# RZT2H register map
Vendor: Renesas Electronics Corporation; Series: RZT; File version: 1.00.00
CPU: other r0p0, little endian, MPU, no FPU, VTOR, 4 interrupt priority bits, 624 interrupts
Registers are 32-bit, read-write, reset 0x0 unless marked. A register's access mark holds for its fields unless they carry their own. Offsets are from the block's base; [hi:lo] are bit positions; {n}, {i} and the like mark numbered series; 'fields as' and 'values as' point back to an identical list; <NAME> marks a mode.

## LCDC — LCD Controller
Base 0x920C0000
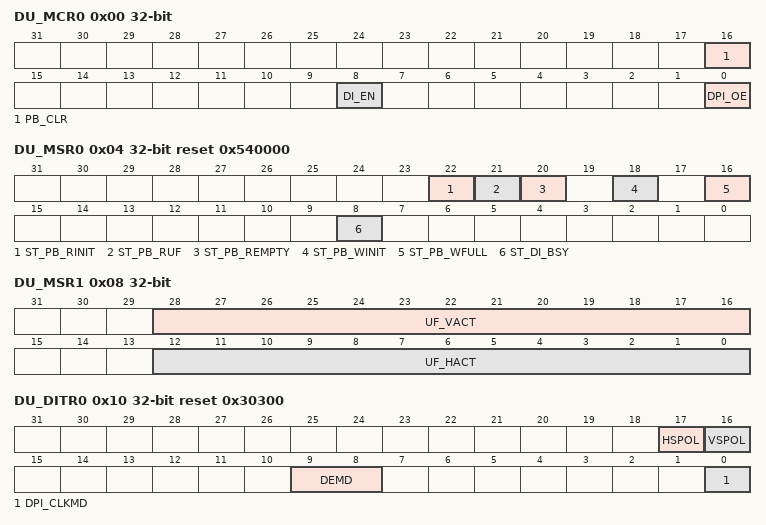
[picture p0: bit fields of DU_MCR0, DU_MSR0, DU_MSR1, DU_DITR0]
0x00 DU_MCR0 — DU Module Control Register 0
  [16] PB_CLR — Clear PBUF pointers
  [8] DI_EN
    0=Disable; 1=Enable
  [0] DPI_OE — Display parallel interface output enable
    0=Disable; 1=Enable
0x04 DU_MSR0 ro reset 0x540000 — DU Module Status Register 0
  [22] ST_PB_RINIT
    0=Not cleared; 1=Cleared (initial value)
  [21] ST_PB_RUF
    0=Not occur PBUF underflow; 1=Occur PBUF underflow
  [20] ST_PB_REMPTY
    0=Not empty; 1=Empty
  [18] ST_PB_WINIT
    0=Not cleared; 1=Cleared (initial value)
  [16] ST_PB_WFULL
    0=Not full; 1=Full
  [8] ST_DI_BSY
    0=Idle; 1=Busy
0x08 DU_MSR1 ro — DU Module Status Register 1
  [28:16] UF_VACT — Vactive counter when the PBUF underflow occurs
  [12:0] UF_HACT — Hactive counter when the PBUF underflow occurs
0x0C DU_IMR0 — DU Interrupt Mask Register 0
  [0] IM_PB_RUF
    0=Not mask interrupt; 1=Mask interrupt
0x10 DU_DITR0 reset 0x30300 — DU Display I/F Timing Register 0
  [17] HSPOL — hsync polarity
    0=Low active; 1=High active
  [16] VSPOL — vsync polarity
    0=Low active; 1=High active
  [9:8] DEMD
    0=Fixed to Low; 3=Data enable (High active)
  [0] DPI_CLKMD
    0=Through output; 1=Inversion output
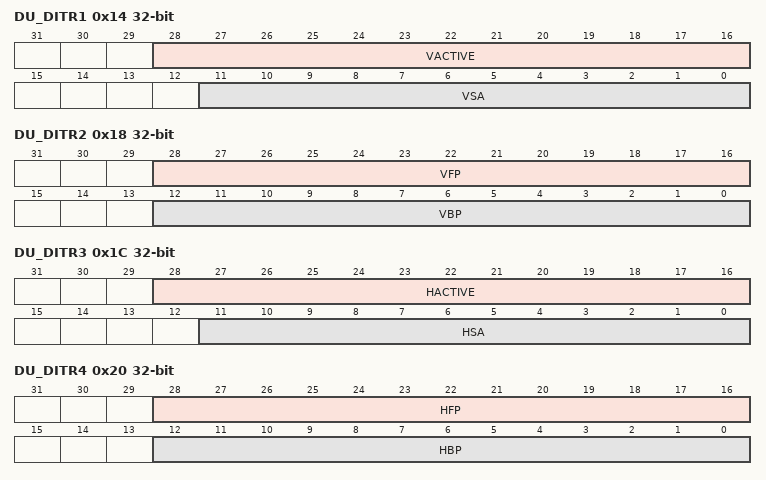
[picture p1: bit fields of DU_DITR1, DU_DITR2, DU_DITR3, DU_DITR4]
0x14 DU_DITR1 — DU Display I/F Timing Register 1
  [28:16] VACTIVE — The number of lines in the Vactive period
  [11:0] VSA — The number of lines in the Vsync period
0x18 DU_DITR2 — DU Display I/F Timing Register 2
  [28:16] VFP — The number of lines in the Vfront period
  [12:0] VBP — The number of lines in the Vback period
0x1C DU_DITR3 — DU Display I/F Timing Register 3
  [28:16] HACTIVE — The number of cycles (pixels) in the Hactive period
  [11:0] HSA — The number of cycles in the Hsync period
0x20 DU_DITR4 — DU Display I/F Timing Register 4
  [28:16] HFP — The number of cycles in the Hfront period
  [12:0] HBP — The number of cycles in the Hback period
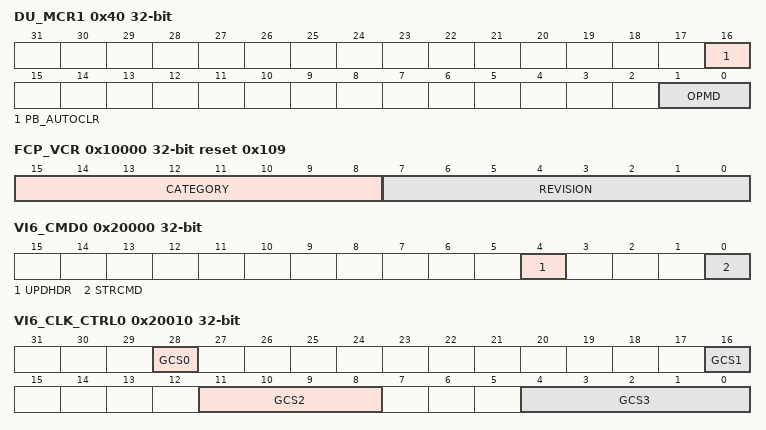
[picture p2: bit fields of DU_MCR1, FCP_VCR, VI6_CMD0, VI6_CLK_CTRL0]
0x40 DU_MCR1 — DU Module Control Register 1
  [16] PB_AUTOCLR — PBUF pointers auto clear enable
    0=Not clear until DU_MCR0.PB_CLR is asserted; 1=Clear during blanking. (according to DU_MCR1.OPMD)
  [1:0] OPMD — Operation mode
    0=After frame end, LIFC wait, and PBUF pointers are cleared if DU_MCR1.PB_AUTOCLR is set to 1; 1=After line end, LIFC wait, and PBUF pointers are cleared if DU_MCR1.PB_AUTOCLR is set to 1; 3=LIFC always request to VSPD. PBUF pointers are not cleared until DU_MCR0.PB_CLR is set to 1.
0x4C DU_PBCR0 reset 0x1F — DU PBUF Control Register 0
  [4:0] PB_DEP — Valid PBUF depth
0x50 DU_PBCR1 — DU PBUF Control Register 1
  [0] PB_RUFOP
    0=Continue outputting invalid data; 1=Output DU_PBCR2.PB_RUFDAT
0x54 DU_PBCR2 — DU PBUF Control Register 2
  [23:0] PB_RUFDAT
0x10000 FCP_VCR ro reset 0x109 — FCPVD Version Control Register
  [15:8] CATEGORY
  [7:0] REVISION
    9=FCP revision is the Simple LCDC
0x20000 VI6_CMD0 — VSPD Start Register 0
  [4] UPDHDR — Reserved state of updating Display List Header (DLH) address
    0=NOP [Write] Not reserved to update DLH address [Read]; 1=Do not set this bit to 1 [Write] Reserved to update DLH address [Read]
  [0] STRCMD — Start reservation of WPF
    0=Start reservation of WPF0 is canceled. [Write] Starting VSPD is not reserved. [Read]; 1=Start reservation of WPF0 is set. [Write] Starting VSPD is reserved. [Read]
0x20010 VI6_CLK_CTRL0 — Clock Control Register 0
  [28] GCS0, [16] GCS1, [11:8] GCS2, [4:0] GCS3
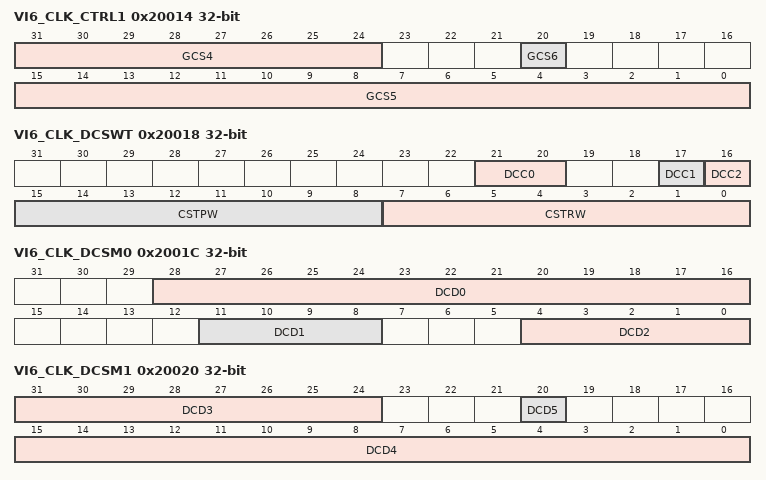
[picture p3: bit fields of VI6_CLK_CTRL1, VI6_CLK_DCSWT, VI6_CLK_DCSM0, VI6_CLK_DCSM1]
0x20014 VI6_CLK_CTRL1 — Clock Control Register 1
  [31:24] GCS4, [20] GCS6, [15:0] GCS5
0x20018 VI6_CLK_DCSWT — Dynamic Clock Stop Control Register
  [21:20] DCC0
  [17] DCC1
  [16] DCC2
  [15:8] CSTPW — Dynamic Clock Stop Control 1
  [7:0] CSTRW — Dynamic Clock Stop Control 2
0x2001C VI6_CLK_DCSM0 — Dynamic Clock Stop Disable Register 0
  [28:16] DCD0, [11:8] DCD1, [4:0] DCD2
0x20020 VI6_CLK_DCSM1 — Dynamic Clock Stop Disable Register 1
  [31:24] DCD3, [20] DCD5, [15:0] DCD4
0x20028 VI6_SRESET — Software Reset Register
  [0] SRST0 — WPF0 Software Reset
    0=NOP; 1=WPF0 software reset
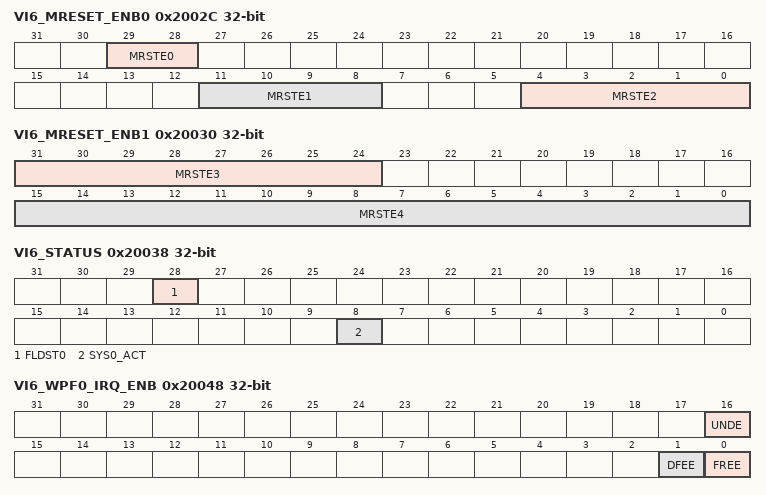
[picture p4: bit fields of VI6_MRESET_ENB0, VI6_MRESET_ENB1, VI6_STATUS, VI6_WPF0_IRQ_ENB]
0x2002C VI6_MRESET_ENB0 — Module Reset Enable Register 0
  [29:28] MRSTE0, [11:8] MRSTE1, [4:0] MRSTE2
0x20030 VI6_MRESET_ENB1 — Module Reset Enable Register 1
  [31:24] MRSTE3, [15:0] MRSTE4
0x20034 VI6_MRESET — Module Reset Issuing Register
  [0] MRST
0x20038 VI6_STATUS ro — Operating Status Register
  [28] FLDST0 — Field status of previous frame of WPF0
    0=Previous finished frame is TOP field; 1=Previous finished frame is BOT field
  [8] SYS0_ACT — WPF0 Operating Status
    0=WPF0 is stopped; 1=WPF0 is operating
0x20048 VI6_WPF0_IRQ_ENB — WPF0 Interrupt Enable Register
  [all] fields
    0=Interrupt disabled; 1=Interrupt enabled
  [16] UNDE
  [1] DFEE
  [0] FREE
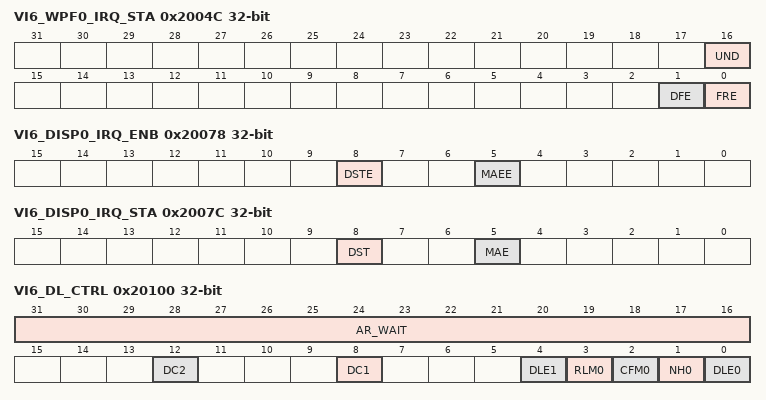
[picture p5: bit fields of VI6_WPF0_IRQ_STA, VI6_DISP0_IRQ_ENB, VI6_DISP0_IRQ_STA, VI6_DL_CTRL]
0x2004C VI6_WPF0_IRQ_STA — WPF0 Interrupt Status Register
  [all] fields
    0=No interrupt. [Read] The interrupt status is cleared to 0. [Write]; 1=Interrupt activated. [Read] Hold the interrupt status value. [Write]
  [16] UND — Interrupt Status and Clear for WPF0 Underrun in case of DU connection
  [1] DFE — Interrupt Status and Clear for WPF0 Display List Frame End
  [0] FRE — Interrupt Status and Clear for WPF0 Frame End
0x20078 VI6_DISP0_IRQ_ENB — Display-0 Interrupt Enable Register
  [8] DSTE
    0=Interrupt disabled; 1=Interrupt enabled
  [5] MAEE
    0=Interrupt disabled; 1=Interrupt enabled
0x2007C VI6_DISP0_IRQ_STA — Display-0 Interrupt Status Register
  [8] DST — Interrupt Status and Clear for Display Start
    values as the fields of VI6_WPF0_IRQ_STA
  [5] MAE — Interrupt Status and Clear for Display Read Data End
    values as the fields of VI6_WPF0_IRQ_STA
0x20100 VI6_DL_CTRL — Display List Control Register
  [31:16] AR_WAIT — Display List Control Setting
  [12] DC2
  [8] DC1
  [4] DLE1 — This bit does not affect anything VSPD. (NOP)
  [3] RLM0 — Loading two plane Registers Mode for WPF0
    0=Reserved status (VI6_CMD0.UPDHDR) is accepted by next_frame_auto_start. Two plane registers are also downloaded by next_frame_auto_start.; 1=Reserved status (VI6_CMD0.UPDHDR) is not accepted by next_frame_auto_start. pNext_header in previous frame's DLH is used for loading Display List. Two plane registers are not downloaded by next_frame_auto_start either.
  [2] CFM0 — Continuous Frame Mode for Header-less Display List for WPF0
    0=Stopped at the end of every frame; 1=The next frame is automatically started
  [1] NH0 — Header-less Display List Mode
    0=Use Display List Header (Normal DL Mode); 1=Do not use Display List Header (Header-less Mode)
  [0] DLE0 — Display List Enable/Disable for WPF0
    0=The display list function is disabled; 1=The display list function is enabled
0x20104 VI6_DL_HDR_ADDR0 — Display List-0 Header Address Register
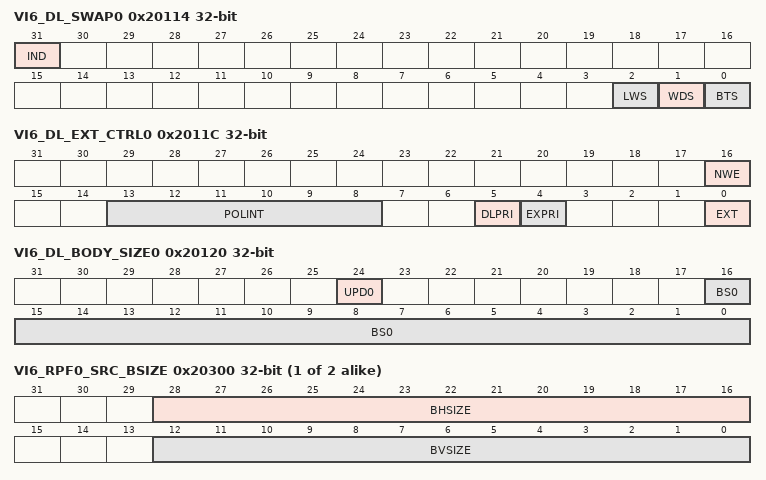
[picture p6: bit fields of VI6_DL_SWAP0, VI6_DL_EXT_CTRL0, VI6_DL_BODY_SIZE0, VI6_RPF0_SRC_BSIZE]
0x20114 VI6_DL_SWAP0 — Display List-0 Data Swapping Register
  [31] IND — Enabling independent swap setting per WPF
    0=Display list swap for WPF1 is specified by LWS, WDS, and BTS in VI6_DL_SWAP0; 1=Display list swap for WPF1 is specified by LWS, WDS, and BTS in VI6_DL_SWAP1
  [2] LWS — Display List Data Swapping in long word Units
    0=Data swapping in long word (32-bit) units is disabled; 1=Data swapping in long word (32-bit) units is enabled
  [1] WDS — Display List Data Swapping in Word Units
    0=Data swapping in word (16-bit) units is disabled; 1=Data swapping in word (16-bit) units is enabled
  [0] BTS — Display List Data Swapping in Byte Units
    0=Data swapping in byte (8-bit) units is disabled; 1=Data swapping in byte (8-bit) units is enabled
0x2011C VI6_DL_EXT_CTRL0 — Extended Display List-0 Control Register
  [16] NWE — No Wait for Polling
  [13:8] POLINT — Extended Display List Command Control
  [5] DLPRI — Display List Control 0
  [4] EXPRI — Display List Control 1
  [0] EXT — Extended Display List for WPF0
    0=No extended display lists are used; 1=Extended display lists are used
0x20120 VI6_DL_BODY_SIZE0 — Display List Body Size Register 0
  [24] UPD0 — Update Flag
    0=Updating display list for the next frame is not reserved; 1=Updating display list for the next frame is reserved
  [16:0] BS0 — Header-less Display List Body Size (WPF0)
0x20130 VI6_DL_HDR_REF_ADDR0 ro — Display List-0 Header Reference Address Register
{0x20300+0x100*i} VI6_RPF{i}_SRC_BSIZE (i=0..1) — RPFn Basic Read Size Register
  [28:16] BHSIZE — Horizontal Size of RPF Basic Read Area
  [12:0] BVSIZE — Vertical Size of RPF Basic Read Area
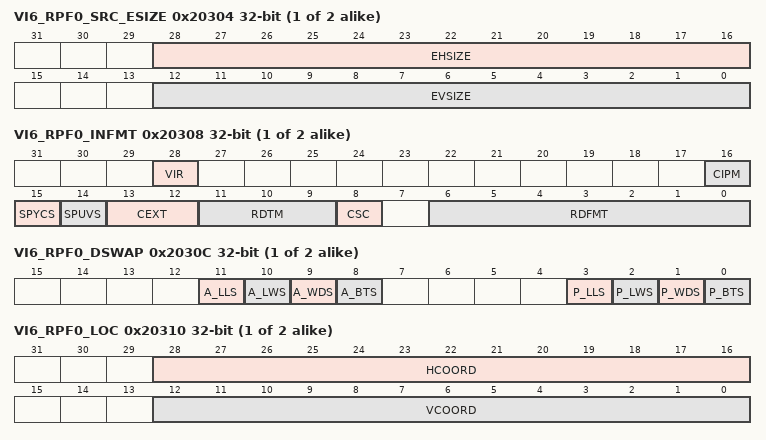
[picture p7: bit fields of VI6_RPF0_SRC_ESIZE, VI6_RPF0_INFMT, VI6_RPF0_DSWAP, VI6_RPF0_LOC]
{0x20304+0x100*i} VI6_RPF{i}_SRC_ESIZE (i=0..1) — RPFn Extended Read Size Register
  [28:16] EHSIZE — RPF Extended Horizontal Read Size
  [12:0] EVSIZE — RPF Extended Vertical Read Size
{0x20308+0x100*i} VI6_RPF{i}_INFMT (i=0..1) — RPFn Input Format Register
  [28] VIR — Virtual Input Enable
    0=RPF0 uses general input; 1=RPF0 uses virtual input
  [16] CIPM — Horizontal Chrominance Interpolation Method Setting
    0=The nearest-neighbor method is used for horizontal chrominance interpolation; 1=The bilinear method is used for horizontal chrominance interpolation
  [15] SPYCS — RPF Input Mode Setting 1
  [14] SPUVS — RPF Input Mode Setting 2
  [13:12] CEXT — Lower-Bit Color Data Extension Method Setting
    0=Lower-order bits of color data are extended with 0; 1=Upper-order bits of color data are copied to the lower-order bits; 2=Lower-order bits of color data are extended with 0. The maximum value is limited to 0xFF.; 3=Setting prohibited
  [11:9] RDTM — CSC Conversion Expression Setting
    0=BT.601 YCbCr [16,235/240] <-> RGB [0,255]; 1=BT.601 YCbCr [0,255] <-> RGB [0,255]; 2=BT.709 YCbCr [16,235/240] <-> RGB [0,255]; 3=BT.709 YCbCr [16,235/240] <-> RGB [16,235]; other=Others (Setting prohibited.)
  [8] CSC — Color Space Conversion Enable
    0=Color space conversion is disabled; 1=Color space conversion is enabled
  [6:0] RDFMT — RPF Input Image Format Setting
{0x2030C+0x100*i} VI6_RPF{i}_DSWAP (i=0..1) — RPFn Data Swapping Register
  [11] A_LLS — alpha Plane Data Swapping in LONG LWORD Units
    0=Data swapping in LONG LWORD (64-bit) units is disabled; 1=Data swapping in LONG LWORD (64-bit) units is enabled
  [10] A_LWS — alpha Plane Data Swapping in long word Units
    values as VI6_DL_SWAP0.LWS
  [9] A_WDS — alpha Plane Data Swapping in Word Units
    0=Data swapping in Word (16-bit) units is disabled; 1=Data swapping in Word (16-bit) units is enabled
  [8] A_BTS — alpha Plane Data Swapping in Byte Units
    0=Data swapping in Byte (8-bit) units is disabled; 1=Data swapping in Byte (8-bit) units is enabled
  [3] P_LLS — Picture Plane Data Swapping in LONG LWORD Units
    values as A_LLS
  [2] P_LWS — Picture Plane Data Swapping in long word Units
    values as VI6_DL_SWAP0.LWS
  [1] P_WDS — Picture Plane Data Swapping in Word Units
    values as A_WDS
  [0] P_BTS — Picture Plane Data Swapping in Byte Units
    values as A_BTS
{0x20310+0x100*i} VI6_RPF{i}_LOC (i=0..1) — RPFn Display Location Register
  [28:16] HCOORD — Horizontal Coordinate of Sublayer Display Location on Master Layer
  [12:0] VCOORD — Vertical Coordinate of Sublayer Display Location on Master Layer
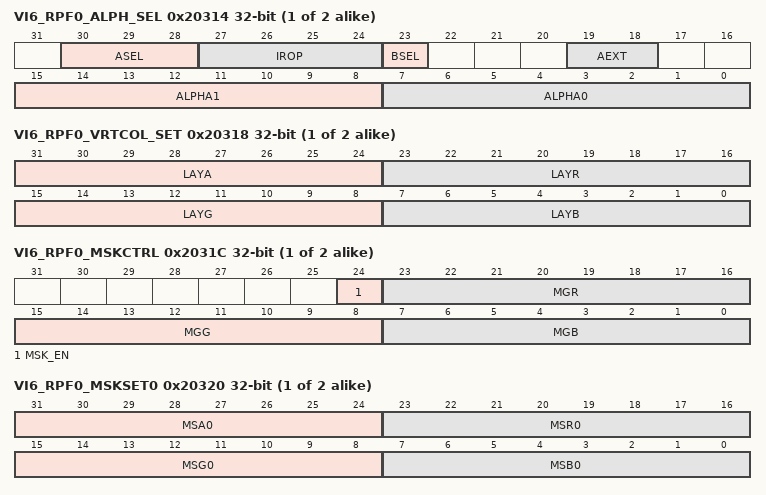
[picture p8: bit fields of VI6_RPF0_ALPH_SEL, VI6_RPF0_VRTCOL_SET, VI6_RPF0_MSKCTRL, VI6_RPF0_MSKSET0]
{0x20314+0x100*i} VI6_RPF{i}_ALPH_SEL (i=0..1) — RPFn alpha Plane Selection Control Register
  [30:28] ASEL — alpha Format and Processing Method Select
    0=1, 4, or 8-bit packed alpha + plane alpha (IROP != 0, 5, 10, 15) The alpha bit field in 1, 4, or 8-bit packed alpha is handled as transparency information. Be sure to specify the packed format that includes alpha through VI6_RPFn_INFMT.RDFMT. When VI6_RPFn_MSKCTRL.MSK_EN is 0 and the IROP bit value is not 0, 5, 10, or 15, the alpha plane should be read as mask information. Specify the number of alpha data bits (BSEL) stored in the alpha plane and the alpha plane read start address (VI6_RPFn_SRCM_ADDR_AI). When the IROP bits are set to 0, 5, 10, or 15, the alpha plane is not read.; 1=8-bit plane alpha The 8-bit alpha plane is read from external RAM as transparency information. When the packed RGB format has a bit field for alpha, the information in the alpha bit field is discarded. The alpha plane read start address (VI6_RPFn_SRCM_ADDR_AI) should be specified. The alpha value goes through the 8-bit transparent alpha generator shown in without change. When VI6_RPFn_MSKCTRL.MSK_EN is 0, IROP operation cannot be executed; set the IROP bits to 0 in this case. When VI6_RPFn_MSKCTRL.MSK_EN is 1. IROP operation can be executed.; 2=1-bit packed alpha + plane alpha (IROP != 0, 5, 10, 15) The 1-bit packed alpha input is converted by the 8-bit transparent alpha generator shown in according to the ALPHA0/1 setting into the 8-bit alpha value as transparency information. Select the packed input format that includes a 1-bit alpha field. When VI6_RPFn_MSKCTRL.MSK_EN is 0 and the IROP value is not 0, 5, 10, or 15, the alpha plane should be read as mask information. Specify the number of alpha data bits (BSEL) stored in the alpha plane and the alpha plane read start address (VI6_RPFn_SRCM_ADDR_AI). When the IROP bits are set to 0, 5, 10, or 15, the alpha plane is not read.; 3=1-bit plane alpha The 1-bit alpha plane is read from external RAM and converted by the 8-bit transparent alpha generator shown in according to the ALPHA0/1 setting into the 8-bit alpha value as transparency information. When the packed RGB format has a bit field for alpha, the information in the alpha bit field is discarded. The alpha plane read start address (VI6_RPFn_SRCM_ADDR_AI) should be specified. When VI6_RPFn_MSKCTRL.MSK_EN is 0, IROP operation cannot be executed; set the IROP bits to 0 in this case. When VI6_RPFn_MSKCTRL.MSK_EN is 1. IROP operation can be executed.; 4=Fixed alpha The fixed alpha value (VI6_RPFn_VRTCOL_SET.LAY A value) is output from the RPF. IROP operation cannot be executed; set the IROP bits to 0 in this case.; other=Others (Setting prohibited.)
  [27:24] IROP — IROP Operation Setting
    0=NOP(D); 1=AND(S & D); 2=AND_REVERSE(S & ~D); 3=COPY(S); 4=AND_INVERTED(~S & D); 5=CLEAR(0); 6=XOR(S ^ D); 7=OR(S | D); 8=NOR(~(S | D)); 9=EQUIV(~(S ^ D)); 10=INVERT(~D); 11=OR_REVERSE(S | ~D); 12=COPY_INVERTED(~S); 13=OR_INVERTED(~S | D); 14=NAND(~(S & D)); 15=SET(all 1)
  [23] BSEL — alpha Bit Count Conversion Selection for 1-Bit Mask Generator
    0=8-bit alpha is converted to 1-bit alpha through the 1-bit mask generator. When the 8-bit alpha value input to the RPF is not 0, it is converted to 1b; when the value is 0, it is converted to 0b.; 1=alpha value goes through the 1-bit mask generator. The 1-bit alpha value input to the RPF is output through the 1-bit mask generator without change.
  [19:18] AEXT — Lower-Bit alpha Value Extension Method Set
    0=The lower-order bits of alpha value are extended with 0; 1=The upper-order bits of alpha value are copied to the lower-order bits; 2=The lower-order bits of alpha value are extended with 0. The maximum value is limited to 0xFF.; 3=Setting prohibited
  [15:8] ALPHA1 — 8-Bit alpha Value Output when 1-Bit alpha Value is 1
  [7:0] ALPHA0 — 8-Bit alpha Value Output when 1-Bit alpha Value is 0
{0x20318+0x100*i} VI6_RPF{i}_VRTCOL_SET (i=0..1) — RPFn Virtual Plane Color Information Register
  [31:24] LAYA — Virtual-Input Fixed alpha Value
  [23:16] LAYR — Virtual-Input Fixed R/Cr Component Value
  [15:8] LAYG — Virtual-Input Fixed G/Y Component Value
  [7:0] LAYB — Virtual-Input Fixed B/Cb Component Value
{0x2031C+0x100*i} VI6_RPF{i}_MSKCTRL (i=0..1) — RPFn Mask Control Register
  [24] MSK_EN — Mask Generation Specification
    0=A 1-bit mask value is generated according to the input alpha plane value. When the input alpha is in the 1-bit format (VI6_RPFn_ALPH_SEL.BSEL = 1), the 1-bit mask value is output without change. When the input alpha is in the 8-bit format (VI6_RPFn_ALPH_SEL.BSEL = 0), the 1-bit mask value is 0 if the alpha value is 0x00; otherwise, the 1-bit mask value is 1.; 1=The R/Cr, G/Y, and B/Cb components of the image input to the destination side of the IROP operation unit are compared with the values specified in the MGR, MGG, and MGB bits, respectively. When all values match, 1 is output as the 1-bit mask value, and in other cases, 0 is output. When the generated 1-bit mask data is not used, set VI6_RPFn_ALPH_SEL.IROP to 0.
  [23:16] MGR — R/Cr Comparison Value for 1-Bit alpha Generation
  [15:8] MGG — G/Y Comparison Value for 1-Bit alpha Generation
  [7:0] MGB — B/Cb Comparison Value for 1-Bit alpha Generation
{0x20320+0x100*i} VI6_RPF{i}_MSKSET0 (i=0..1) — RPFn IROP-SRC Input Value Register 0
  [31:24] MSA0 — IROP-Source Input alpha Value when 1-Bit alpha is 0
  [23:16] MSR0 — IROP-Source Input R/Cr Value when 1-Bit alpha is 0
  [15:8] MSG0 — IROP-Source Input G/Y Value when 1-Bit alpha is 0
  [7:0] MSB0 — IROP-Source Input B/Cb Value when 1-Bit alpha is 0
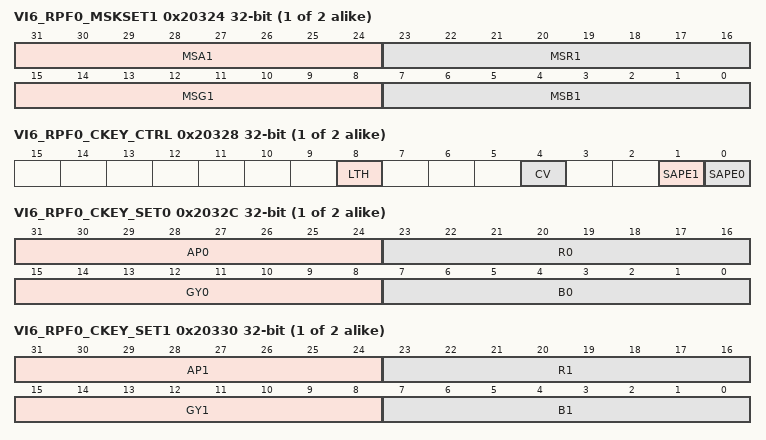
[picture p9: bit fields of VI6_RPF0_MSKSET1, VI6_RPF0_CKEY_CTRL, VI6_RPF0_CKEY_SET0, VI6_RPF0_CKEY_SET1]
{0x20324+0x100*i} VI6_RPF{i}_MSKSET1 (i=0..1) — RPFn IROP-SRC Input Value Register 1
  [31:24] MSA1 — IROP-Source Input alpha Value when 1-Bit alpha is 1
  [23:16] MSR1 — IROP-Source Input R/Cr Value when 1-Bit alpha is 1
  [15:8] MSG1 — IROP-Source Input G/Y Value when 1-Bit alpha is 1
  [7:0] MSB1 — IROP-Source Input B/Cb Value when 1-Bit alpha is 1
{0x20328+0x100*i} VI6_RPF{i}_CKEY_CTRL (i=0..1) — RPFn Color Keying Control Register
  [8] LTH — Transparent color-luma Threshold Mode Enable/Disable
    0=Luma threshold mode is disabled (Matched color mode); 1=Luma threshold mode is enabled
  [4] CV — Color Replacement Control
    0=Color replacement function is disabled (transparent color mode); 1=Color replacement function is enabled
  [1] SAPE1 — Comparison Color Data Setting 1 Enable/Disable
    0=Comparison color data setting 1 is disabled; 1=Comparison color data setting 1 is enabled
  [0] SAPE0 — Comparison Color Data Setting 0 Enable/Disable
    0=Comparison color data setting 0 is disabled; 1=Comparison color data setting 0 is enabled
{0x2032C+0x100*i} VI6_RPF{i}_CKEY_SET0 (i=0..1) — RPFn Color Keying Color Setting Register 0
  [31:24] AP0 — alpha Data in Color Keying Color Information-0
  [23:16] R0 — R/Cr Component Data in Color Keying Color Information-0
  [15:8] GY0 — G/Y Component Data in Color Keying Color Information-0
  [7:0] B0 — B/Cb Component Data in Color Keying Color Information-0
{0x20330+0x100*i} VI6_RPF{i}_CKEY_SET1 (i=0..1) — RPFn Color Keying Color Setting Register 1
  [31:24] AP1 — alpha Data in Color Keying Color Information-1
  [23:16] R1 — R/Cr Component Data in Color Keying Color Information-1
  [15:8] GY1 — G/Y Component Data in Color Keying Color Information-1
  [7:0] B1 — B/Cb Component Data in Color Keying Color Information-1
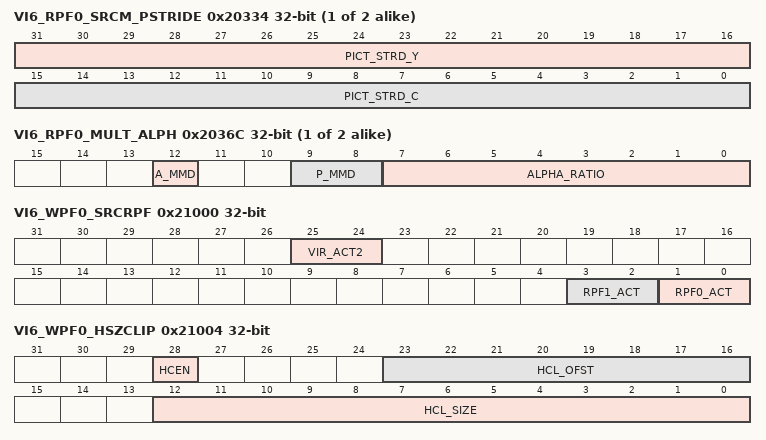
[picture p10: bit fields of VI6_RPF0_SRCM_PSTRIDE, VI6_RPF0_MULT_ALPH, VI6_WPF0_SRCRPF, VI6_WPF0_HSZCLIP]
{0x20334+0x100*i} VI6_RPF{i}_SRCM_PSTRIDE (i=0..1) — RPFn Source Picture Memory Stride Setting Register
  [31:16] PICT_STRD_Y — Memory Stride of Source Picture Y/RGB Plane
  [15:0] PICT_STRD_C — Memory Stride of Source Picture C Plane
{0x20338+0x100*i} VI6_RPF{i}_SRCM_ASTRIDE (i=0..1) — RPFn Source alpha Memory Stride Setting Register
  [15:0] ALPH_STRD — Memory Stride of Source alpha Plane
{0x2033C+0x100*i} VI6_RPF{i}_SRCM_ADDR_Y (i=0..1) — RPFn Source Y/RGB Address Register
  [31:0] SRCM_ADDR_Y — Source Image Y/RGB Plane Storing Address
{0x20340+0x100*i} VI6_RPF{i}_SRCM_ADDR_C0 (i=0..1) — RPFn Source Chroma Address Register 0
  [31:0] SRCM_ADDR_C0 — Source Image C Plane Storing Address 0
{0x20344+0x100*i} VI6_RPF{i}_SRCM_ADDR_C1 (i=0..1) — RPFn Source Chroma Address Register 1
  [31:0] SRCM_ADDR_C1 — Source Image C Plane Storing Address 1
{0x20348+0x100*i} VI6_RPF{i}_SRCM_ADDR_AI (i=0..1) — RPFn Source alpha Address Register
  [31:0] SRCM_ADDR_AI — Source Image alpha Plane Storing Address
{0x20350+0x100*i} VI6_RPF{i}_BAC (i=0..1) — RPFn Bus Access Control Register
  [16] B512 — Burst access in 512 pixels' enable
    0=Burst access in 256 pixels; 1=Burst access in 512 pixels
{0x2036C+0x100*i} VI6_RPF{i}_MULT_ALPH (i=0..1) — RPFn Multiply Alpha Control Register
  [12] A_MMD
    0=Alpha data go through multiply-alpha unit; 1=Multiply-alpha unit multiplies alpha data by specified alpha (ALPHA_RATIO[7:0])
  [9:8] P_MMD — P_MMD[1:0]
    0=Image data goes through multiply-alpha unit; 1=Multiply-alpha unit multiplies image data by specified alpha (ALPHA_RATIO[7:0]); 2=Multiply-alpha unit multiplies image data by alpha data; 3=Multiply-alpha unit multiplies image data by alpha data and specified alpha (ALPHA_RATIO[7:0])
  [7:0] ALPHA_RATIO — Multiply-alpha value
0x21000 VI6_WPF0_SRCRPF — WPF0-Source-RPF Register
  [25:24] VIR_ACT2 — Virtual RPF Start Enable in BRS
    0=The virtual RPF in the BRS is not started; 1=The virtual RPF in the BRS is started as a sublayer source RPF for the WPF0; 2=The virtual RPF in the BRS is started as the master-layer source RPF for the WPF0; 3=Setting prohibited
  [3:2] RPF1_ACT — RPF1 Start Enable
    0=RPF1 is not started; 1=RPF1 is started as a sublayer source RPF for the WPF0; 2=RPF1 is started as the master-layer source RPF for the WPF0; 3=Setting prohibited
  [1:0] RPF0_ACT — RPF0 Start Enable
    0=RPF0 is not started; 1=RPF0 is started as a sublayer source RPF for the WPF0; 2=RPF0 is started as the master-layer source RPF for the WPF0; 3=Setting prohibited
0x21004 VI6_WPF0_HSZCLIP — WPF0 Horizontal Input Size Clipping Register
  [28] HCEN — Horizontal Size Clipping Enable/Disable
    0=Horizontal size clipping is disabled; 1=Horizontal size clipping is enabled
  [23:16] HCL_OFST — Horizontal Size Clipping Offset Value Setting
  [12:0] HCL_SIZE — Horizontal Clipping Size Setting
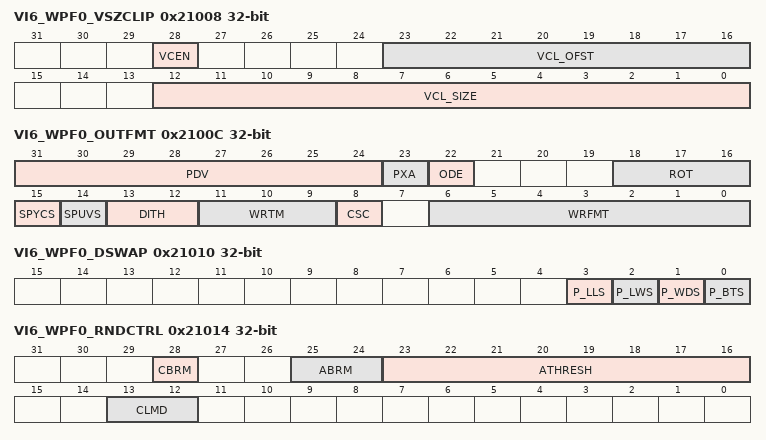
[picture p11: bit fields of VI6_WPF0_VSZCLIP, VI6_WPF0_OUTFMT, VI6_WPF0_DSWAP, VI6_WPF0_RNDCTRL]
0x21008 VI6_WPF0_VSZCLIP — WPF0 Vertical Input Size Clipping Register
  [28] VCEN — Vertical Size Clipping Enable/Disable
    0=Vertical size clipping is disabled; 1=Vertical size clipping is enabled
  [23:16] VCL_OFST — Vertical Size Clipping Offset Value Setting
  [12:0] VCL_SIZE — Vertical Clipping Size Setting
0x2100C VI6_WPF0_OUTFMT — WPF0 Output Format Register
  [31:24] PDV — PAD Value in Output Packed Data
  [23] PXA — PAD Data Select
    0=The value specified in the PDV bits is stored in the PAD shown in ; 1=The alpha value output from DPR in pixel units is stored in the PAD shown in 
  [22] ODE — Ordered Dither (mode A) Enable/Disable
    0=Ordered dither (mode A) is disabled; 1=Ordered dither (mode A) is enabled
  [18:16] ROT — Rotation Processing Select
    0=No flipping; 1=Vertical flipping
  [15] SPYCS — WPF Output Mode Setting 1
  [14] SPUVS — WPF Output Mode Setting 2
  [13:12] DITH — Ordered Dither (mode B) Enable/Disable
    0=Dithering (mode B) is disabled; 3=Dithering (mode B) is enabled; other=Others (Setting prohibited.)
  [11:9] WRTM — CSC Conversion Expression Setting
    0=BT.601 Y CbCr [16,235/240] <-> RGB [0,255]; 1=BT.601 Y CbCr [0,255] <-> RGB [0,255]; 2=BT.709 Y CbCr [16,235/240] <-> RGB [0,255]; 3=BT.709 Y CbCr [16,235/240] <-> RGB [16,235]; other=Others (Setting prohibited.)
  [8] CSC — Color Space Conversion Setting
    0=Color space is not converted; 1=Color space is converted
  [6:0] WRFMT — WPF Output Image Format Setting
0x21010 VI6_WPF0_DSWAP — WPF0 Data Swapping Register
  [3] P_LLS
    values as VI6_RPF0_DSWAP.A_LLS
  [2] P_LWS
    values as VI6_DL_SWAP0.LWS
  [1] P_WDS — WPF Output Data Swapping in Word Units
    values as VI6_DL_SWAP0.WDS
  [0] P_BTS
    values as VI6_DL_SWAP0.BTS
0x21014 VI6_WPF0_RNDCTRL — WPF0 Rounding Control Register
  [28] CBRM — Bit Count Reduction Method Selection for Data Storage in Packed RGB
    0=Bit count conversion: The lower-order bits are truncated; 1=Bit count conversion: Rounding (rounding off)
  [25:24] ABRM — Bit Count Reduction Method Selection for Data Storage in PAD
    0=Bit count conversion: The lower-order bits are truncated; 1=Bit count conversion: Rounding (rounding off); 2=Bit count conversion: Comparison with the threshold value (this setting is allowed only when the storage field is one bit); 3=Setting prohibited
  [23:16] ATHRESH — Threshold for Conversion to 1-Bit alpha Data
  [13:12] CLMD — Color Data Clipping
    0=Output value is not clipped (0-255); 1=Output value is clipped: YCbCr mode 1 (16-235 (Y), 16-240 (Cb/Cr)); 2=Output value is clipped: YCbCr mode 2 (Y/Cb/Cr = 1-254); 3=Setting prohibited
0x2101C VI6_WPF0_DSTM_STRIDE_Y — WPF0 Destination Y Plane Memory Stride Register
  [15:0] PICT_STRD_Y — Memory Stride of Destination Picture Y/RGB Plane
0x21020 VI6_WPF0_DSTM_STRIDE_C — WPF0 Destination C Plane Memory Stride Register
  [15:0] PICT_STRD_C — Memory Stride of Destination Picture C Plane
0x21028 VI6_WPF0_DSTM_ADDR_C0 — WPF0 Destination Chroma Address Register 0
  [31:0] DSTM_ADDR_C0 — Destination Image C Plane Storing Address 0
0x2102C VI6_WPF0_DSTM_ADDR_C1 — WPF0 Destination Chroma Address Register 1
  [31:0] DSTM_ADDR_C1 — Destination Image C Plane Storing Address 1
0x21034 VI6_WPF0_WRBCK_CTRL — WPF0 LIF Write Back Control Register
  [1:0] WBMD — Display Data Write Back Control
    0=Write Back Disabled; 1=Write Back Enabled
0x22000 VI6_DPR_RPF0_ROUTE — RPF0 Routing Register
  [5:0] RT_RPF0 — RPF0 Target Node Value
0x22004 VI6_DPR_RPF1_ROUTE — RPF1 Routing Register
  [5:0] RT_RPF1 — RPF1 Target Node Value
0x22014 VI6_DPR_WPF0_FPORCH — WPF0 Timing Control Register
  [13:8] FP_WPF0 — WPF0 Internal Operation Timing Setting
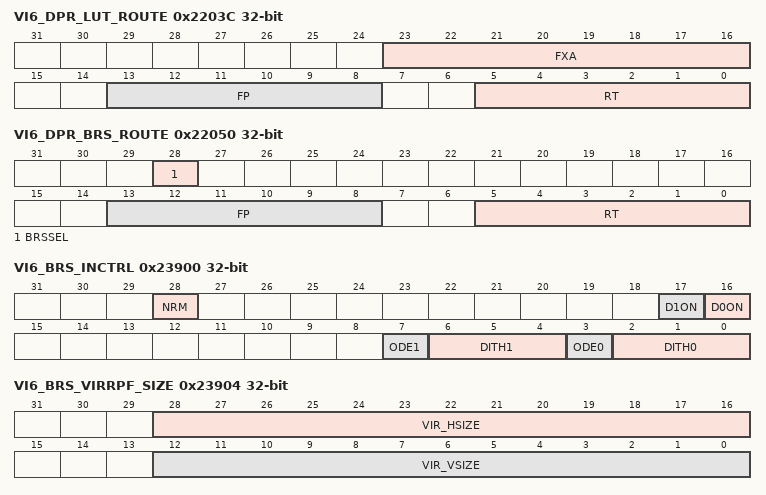
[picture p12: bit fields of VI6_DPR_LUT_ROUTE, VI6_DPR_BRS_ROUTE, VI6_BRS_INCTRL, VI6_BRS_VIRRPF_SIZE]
0x2203C VI6_DPR_LUT_ROUTE — LUT Routing Register
  [23:16] FXA — Fixed alpha Output Value for LUT
  [13:8] FP — LUT Internal Operation Timing Setting
  [5:0] RT — LUT Target Node Value
0x22050 VI6_DPR_BRS_ROUTE — BRS Routing Register
  [28] BRSSEL — Always set this bit to 1.
  [13:8] FP — BRS Internal Operation Timing Setting
  [5:0] RT — BRS Target Node Value
0x22800 VI6_LUT_CTRL — LUT Control Register
  [0] LUT_EN — 1D-LUT Enable/Disable
    0=1D-LUT function is disabled; 1=1D-LUT function is enabled
0x23900 VI6_BRS_INCTRL — BRS Input Control Register
  [28] NRM — Color Data Normalization
    0=Divider (DIV unit in ) does not divide the color value by alpha; 1=Divider (DIV unit in ) divides the color value by alpha
  [17] D1ON — Ordered dither (mode B) Enable of BRS Input 1
    0=Dithering (mode B) of BRSin1 is disabled; 1=Dithering (mode B) of BRSin1 is enabled
  [16] D0ON — Ordered dither (mode B) Enable of BRS Input 0
    0=Dithering (mode B) of BRSin0 is disabled; 1=Dithering (mode B) of BRSin0 is enabled
  [7] ODE1 — Ordered Dither (mode A) of CH1 Input to BRS Enable/Disable
    0=Ordered dither (mode A) of BRSin1 is disabled; 1=Ordered dither (mode A) of BRSin1 is enabled
  [6:4] DITH1 — Dithering of CH1 Input to BRS
  [3] ODE0 — Ordered Dither (mode A) of CH0 Input to BRS Enable/Disable
    0=Ordered dither (mode A) of BRSin0 is disabled; 1=Ordered dither (mode A) of BRSin0 is enabled
  [2:0] DITH0 — Dithering of CH0 Input to BRS
    0=Dithering of BRSin0 input image is disabled; 1=Dithering of BRSin0 input image at 18 bpp (RGB666: 260000 colors); 2=Dithering of BRSin0 input image at 16 bpp (RGB565: 65535 colors); 3=Dithering of BRSin0 input image at 15 bpp (RGB555: 32768 colors); 4=Dithering of BRSin0 input image at 12 bpp (RGB444: 4096 colors); 5=Dithering of BRSin0 input image at 8 bpp (RGB332: 256 colors); other=Others (Setting prohibited.)
0x23904 VI6_BRS_VIRRPF_SIZE — Size Register of BRS Input Virtual RPF
  [28:16] VIR_HSIZE — Virtual RPF Horizontal Size
  [12:0] VIR_VSIZE — Virtual RPF Vertical Size
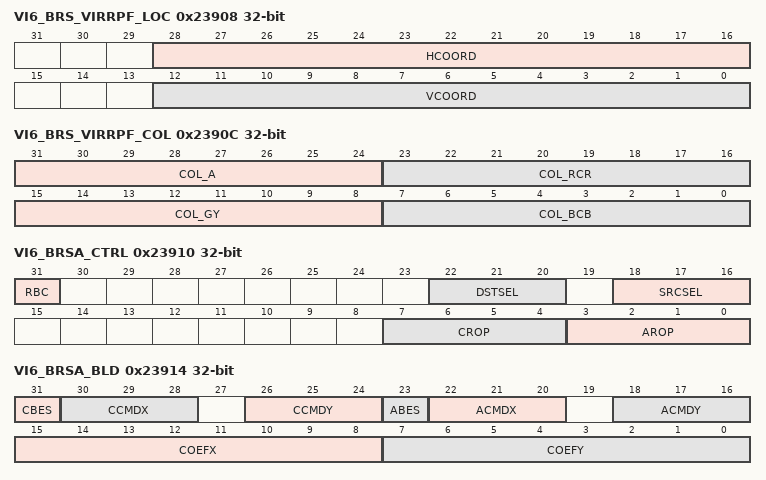
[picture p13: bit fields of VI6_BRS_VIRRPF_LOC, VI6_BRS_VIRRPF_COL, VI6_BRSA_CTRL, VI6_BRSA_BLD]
0x23908 VI6_BRS_VIRRPF_LOC — Display Location Register of BRS Input Virtual RPF
  [28:16] HCOORD — Horizontal Coordinate of Virtual RPF Location on Master Layer
  [12:0] VCOORD — Vertical Coordinate of Virtual RPF Location on Master Layer
0x2390C VI6_BRS_VIRRPF_COL — Color Information Register of BRS Input Virtual RPF
  [31:24] COL_A — Fixed alpha of Virtual RPF
  [23:16] COL_RCR — Fixed R/Cr of Virtual RPF
  [15:8] COL_GY — Fixed G/Y of Virtual RPF
  [7:0] COL_BCB — Fixed B/Cb of Virtual RPF
0x23910 VI6_BRSA_CTRL — BRS Control Register A
  [31] RBC — Operation Type of Blending/ROP Unit A
    0=ROP (raster operation); 1=Blending operation
  [22:20] DSTSEL — Input Selection for DST Side of Blending/ROP Unit A
    0=BRS input 0 (BRSin0) is input to DST; 1=BRS input 1 (BRSin1) is input to DST; 4=Virtual RPF is input to DST; other=Others (Setting prohibited.)
  [18:16] SRCSEL — Input Selection for SRC Side of Blending/ROP Unit A
    0=BRS input 0 (BRSin0) is input to SRC; 1=BRS input 1 (BRSin1) is input to SRC; 4=Virtual RPF is input to SRC; other=Others (Setting prohibited.)
  [7:4] CROP — Color Data ROP Operator
  [3:0] AROP — alpha Data ROP Operator
0x23914 VI6_BRSA_BLD — BRS Blend Control Register A
  [31] CBES — Blending Expression Selection
    0=CCMDX * (DST color data) + CCMDY * (SRC color data); 1=CCMDX * (DST color data) - CCMDY * (SRC color data)
  [30:28] CCMDX — Blending Coefficient X Selection
    0=DST alpha data is used as blending coefficient X; 1=255 - (DST alpha data) is used as blending coefficient X; 2=SRC alpha data is used as blending coefficient X; 3=255 - (SRC alpha data) is used as blending coefficient X; 4=Fixed alpha value 0 (COEFX setting)
  [26:24] CCMDY — Blending Coefficient Y Selection
    0=DST alpha data is used as blending coefficient Y; 1=255 - (DST alpha data) is used as blending coefficient Y; 2=SRC alpha data is used as blending coefficient Y; 3=255 - (SRC alpha data) is used as blending coefficient Y; 4=Fixed alpha value 1 (COEFY setting)
  [23] ABES — Blending alpha Creation Expression
    0=ACMDX * (DST alpha data) + ACMDY * (SRC alpha data); 1=ACMDX * (DST alpha data) - ACMDY * (SRC alpha data)
  [22:20] ACMDX — alpha Creation Coefficient X
    0=(alpha creation coefficient X) = (DST alpha data); 1=(alpha creation coefficient X) = 255 - (DST alpha data); 2=(alpha creation coefficient X) = (SRC alpha data); 3=(alpha creation coefficient X) = 255 - (SRC alpha data); 4=(alpha creation coefficient X) = Fixed alpha value 0 (COEFX setting); other=Others (Setting prohibited.)
  [18:16] ACMDY — alpha Creation Coefficient Y
    0=(alpha creation coefficient Y) = (DST alpha data); 1=(alpha creation coefficient Y) = 255 - (DST alpha data); 2=(alpha creation coefficient Y) = (SRC alpha data); 3=(alpha creation coefficient Y) = 255 - (SRC alpha data); 4=(alpha creation coefficient Y) = Fixed alpha value 1 (COEFY setting); other=Others (Setting prohibited.)
  [15:8] COEFX — Fixed alpha Value 0
  [7:0] COEFY — Fixed alpha Value 1
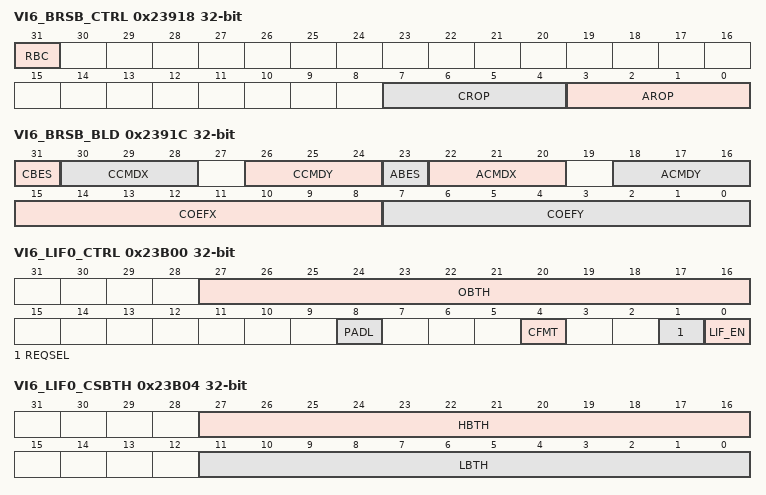
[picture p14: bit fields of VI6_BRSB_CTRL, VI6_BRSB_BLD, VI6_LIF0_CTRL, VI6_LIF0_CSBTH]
0x23918 VI6_BRSB_CTRL — BRS Control Register B
  [31] RBC — Operation Type of Blending/ROP Unit B
    0=ROP (raster operation); 1=Blending operation
  [7:4] CROP — Color Data ROP Operator
  [3:0] AROP — alpha Data ROP Operator
0x2391C VI6_BRSB_BLD — BRS Blend Control Register B
  fields as VI6_BRSA_BLD
0x23B00 VI6_LIF0_CTRL — LIF0 Control Register
  [27:16] OBTH — Buffer Threshold for Start Ready Notification to Display Module
  [8] PADL
    0=Padding with dummy lines to output image to DU is disabled; 1=Padding with dummy lines to output image to DU is enabled
  [4] CFMT — Chroma Format
    0=YCbCr444 or RGB Format; 1=YCbCr422 Format
  [1] REQSEL
    0=This value is setting prohibited when 1 is set to LIF_EN; 1=DU is selected as the destination external display module
  [0] LIF_EN — Enable/Disable of Data Output to External Display Module
    0=Data output to the external display module is disabled; 1=Data output to the external display module is enabled
0x23B04 VI6_LIF0_CSBTH — LIF0 Clock Stop Buffer Control Register
  [27:16] HBTH — Buffer Threshold for Clock Stop in Dynamic Clock Control
  [11:0] LBTH — Buffer Threshold for Clock Start in Dynamic Clock Control
0x23B0C VI6_LIF0_LBA — LIF0 Buffer Attribute Register
  [31] LBA0 — LIF Buffer Attribute Register 0
  [27:16] LBA1 — LIF Buffer Attribute Register 1
  [11:0] LBA2 — LIF Buffer Attribute Register 2
0x23B30 VI6_LIF0_PADLN_CYC — LIF0 Padding Line Cycle Register
  [5:0] PADLN_CYC — Cycle of padding pattern
0x23B34 VI6_LIF0_PADLN_PT — LIF0 Padding Line Pattern Register
  [31:0] PADLN_PATTERN — Pattern of padding with dummy lines
0x23B38 VI6_LIF0_PADLN_VAL — LIF0 Padding Line Value Register
  [31:24] PADA, [23:16] PADR, [15:8] PADG, [7:0] PADB
0x23B3C VI6_LIF0_PADLN_SIZE — LIF0 Padding Line Size Register
  [12:0] PADLN_VSIZE — Vertical Size of LIF output in case of enabling Padding line
